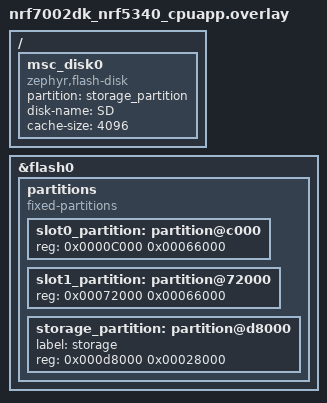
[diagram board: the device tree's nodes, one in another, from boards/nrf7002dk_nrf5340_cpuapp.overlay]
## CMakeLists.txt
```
#
# Copyright (c) 2020 Nordic Semiconductor
#
# SPDX-License-Identifier: LicenseRef-Nordic-5-Clause
#

cmake_minimum_required(VERSION 3.20.0)

find_package(Zephyr REQUIRED HINTS $ENV{ZEPHYR_BASE})
project(download)

# NORDIC SDK APP START
target_sources(app PRIVATE src/main.c)
target_sources(app PRIVATE src/file_storage.c)
# NORDIC SDK APP END
```

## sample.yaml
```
sample:
  name: Download sample
tests:
  sample.net.download.tfm.lte:
    build_only: true
    extra_args: OVERLAY_CONFIG="overlay-tfm.conf"
    integration_platforms:
      - nrf9160dk_nrf9160_ns
    platform_allow: nrf9160dk_nrf9160_ns
    tags: ci_build
  sample.net.download_client.lte:
    build_only: true
    extra_configs:
      - CONFIG_SHELL=y
      - CONFIG_COAP=y
      - CONFIG_DOWNLOAD_CLIENT_SHELL=y
      - CONFIG_SAMPLE_COMPUTE_HASH=y
    integration_platforms:
      - nrf9160dk_nrf9160_ns
    platform_allow: nrf9160dk_nrf9160_ns
    tags: ci_build
  sample.net.download_client.wifi:
    build_only: true
    extra_configs:
      - CONFIG_SHELL=y
      - CONFIG_DOWNLOAD_CLIENT_SHELL=y
      - CONFIG_SAMPLE_COMPUTE_HASH=y
    integration_platforms:
      - nrf7002dk_nrf5340_cpuapp
    platform_allow: nrf7002dk_nrf5340_cpuapp
    tags: ci_build
```

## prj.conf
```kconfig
#
# Copyright (c) 2021 Nordic Semiconductor ASA
#
# SPDX-License-Identifier: LicenseRef-Nordic-5-Clause
#


CONFIG_DOWNLOAD_CLIENT=y
CONFIG_DOWNLOAD_CLIENT_STACK_SIZE=4096

CONFIG_NEWLIB_LIBC=y

# Networking
CONFIG_NETWORKING=y
# CONFIG_NET_SOCKETS_OFFLOAD=y
CONFIG_NET_SOCKETS=y
CONFIG_NET_SOCKETS_POSIX_NAMES=y
CONFIG_NET_IPV4=y
CONFIG_NET_TCP=y
CONFIG_NET_NATIVE=y
CONFIG_MAIN_STACK_SIZE=6144

CONFIG_NET_CONNECTION_MANAGER=y

CONFIG_POSIX_MAX_FDS=16

CONFIG_NET_IPV4_FRAGMENT=y
CONFIG_NET_IPV4_FRAGMENT_MAX_COUNT=5
CONFIG_DOWNLOAD_CLIENT_HTTP_FRAG_SIZE_4096=y
CONFIG_DOWNLOAD_CLIENT_BUF_SIZE=4096
CONFIG_DOWNLOAD_CLIENT_RANGE_REQUESTS=y
CONFIG_DOWNLOAD_CLIENT_LOG_LEVEL_OFF=y

CONFIG_WPA_SUPP_LOG_LEVEL_DBG=y

CONFIG_SAMPLE_SECURE_SOCKET=y
CONFIG_LOG=y
CONFIG_PRINTK=n

CONFIG_NET_TCP_MAX_RECV_WINDOW_SIZE=65535
```

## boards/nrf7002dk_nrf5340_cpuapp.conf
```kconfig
#
# Copyright (c) 2023 Nordic Semiconductor ASA
#
# SPDX-License-Identifier: LicenseRef-Nordic-5-Clause
#

# General
CONFIG_POSIX_CLOCK=y
CONFIG_POSIX_MAX_FDS=10
CONFIG_SYSTEM_WORKQUEUE_STACK_SIZE=4096
CONFIG_HW_STACK_PROTECTION=y

# Optimized networking settings for performance
CONFIG_NRF700X_TX_MAX_DATA_SIZE=512
CONFIG_HEAP_MEM_POOL_SIZE=160000
CONFIG_NET_BUF_DATA_SIZE=1500
CONFIG_NRF700X_QSPI_LOW_POWER=n
CONFIG_NRF_WIFI_LOW_POWER=n
CONFIG_NRF700X_TX_DONE_WQ_ENABLED=n
#CONFIG_NRF700X_TX_DONE_WQ_PRIORITY=-2
CONFIG_NRF700X_RX_WQ_ENABLED=y
CONFIG_NRF700X_RX_WQ_PRIORITY=-3
CONFIG_NRF700X_UTIL=y
CONFIG_NRF700X_MAX_TX_TOKENS=5
CONFIG_NRF700X_RX_NUM_BUFS=63

# Set newlib C to prevent build error complaining that string.h is not supported
CONFIG_NEWLIB_LIBC=y

# Zephyr NET Connection Manager connectivity layer.
CONFIG_L2_WIFI_CONNECTIVITY=y

# Wi-Fi
CONFIG_WIFI=y
CONFIG_WIFI_NRF700X=y
CONFIG_WIFI_LOG_LEVEL_ERR=y
CONFIG_WIFI_MGMT_EXT=y
CONFIG_WIFI_CREDENTIALS=y
CONFIG_WIFI_CREDENTIALS_BACKEND_SETTINGS=y
CONFIG_WIFI_CREDENTIALS_STATIC=y
CONFIG_WIFI_CREDENTIALS_STATIC_SSID=""
CONFIG_WIFI_CREDENTIALS_STATIC_PASSWORD=""
CONFIG_FLASH=y
CONFIG_FLASH_PAGE_LAYOUT=y
CONFIG_FLASH_MAP=y
CONFIG_NVS=y
CONFIG_SETTINGS=y
CONFIG_SETTINGS_NVS=y

# WPA
CONFIG_WPA_SUPP=y
CONFIG_WPA_SUPP_LOG_LEVEL_ERR=y

# NET sockets
CONFIG_NET_L2_ETHERNET=y
CONFIG_NET_TCP_WORKQ_STACK_SIZE=2048
CONFIG_NET_UDP=y
CONFIG_NET_SOCKETS_OFFLOAD=n
CONFIG_NET_DHCPV4=y
CONFIG_NET_CONTEXT_SNDTIMEO=y
CONFIG_NET_CONTEXT_RCVTIMEO=y
CONFIG_NET_MGMT_EVENT_STACK_SIZE=4096

# DNS
CONFIG_DNS_RESOLVER=y

# TLS
CONFIG_NRF_SECURITY=y
CONFIG_MBEDTLS=y
CONFIG_MBEDTLS_ENABLE_HEAP=y
CONFIG_MBEDTLS_HEAP_SIZE=44000
CONFIG_MBEDTLS_RSA_C=y
CONFIG_MBEDTLS_SSL_SERVER_NAME_INDICATION=y
CONFIG_NET_SOCKETS_SOCKOPT_TLS=y

# File storage
CONFIG_DISK_ACCESS=y
CONFIG_FILE_SYSTEM=y
CONFIG_FAT_FILESYSTEM_ELM=y
CONFIG_DISK_DRIVERS=y
CONFIG_DISK_DRIVER_FLASH=y


##################################

CONFIG_DOWNLOAD_CLIENT_BUF_SIZE=16384
CONFIG_DOWNLOAD_CLIENT_RANGE_REQUESTS=n

CONFIG_MBEDTLS_SSL_IN_CONTENT_LEN=16384
CONFIG_MBEDTLS_SSL_OUT_CONTENT_LEN=4096

CONFIG_PSA_WANT_KEY_TYPE_ECC_PUBLIC_KEY=y
CONFIG_CC3XX_BACKEND=y
CONFIG_OBERON_BACKEND=n
CONFIG_PSA_WANT_ECC_SECP_R1_256=y
CONFIG_PSA_WANT_ECC_SECP_R1_384=y

CONFIG_SAMPLE_FILE_CUSTOM=y
CONFIG_SAMPLE_FILE_URL="https://becurienew.s3.ap-south-1.amazonaws.com/test/Sample-WAV_33MB.wav"
CONFIG_SAMPLE_SHA256_HASH="96130acb14c731749c82414063ada50e69493c63944b1f8eff4cfdc891bff40d"

#Disable unused feature to reduce RAM requirement
CONFIG_NET_IPV6=n
CONFIG_MBEDTLS_SSL_SRV_C=n
CONFIG_MBEDTLS_CHACHA20_C=n
CONFIG_MBEDTLS_POLY1305_C=n
CONFIG_MBEDTLS_GCM_C=n
CONFIG_NRF700X_BT_COEX=n
CONFIG_SAMPLE_COMPUTE_HASH=y
CONFIG_SAMPLE_COMPARE_HASH=y
```

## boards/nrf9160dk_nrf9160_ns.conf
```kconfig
#
# Copyright (c) 2023 Nordic Semiconductor ASA
#
# SPDX-License-Identifier: LicenseRef-Nordic-5-Clause
#

# Configuration file for nRF9160 DK
# This file is merged with prj.conf in the application folder, and options
# set here will take precedence if they are present in both files.

# General
CONFIG_HW_STACK_PROTECTION=y
CONFIG_PICOLIBC=y

# Disable Duplicate Address Detection (DAD)
# due to not being properly implemented for offloaded interfaces.
CONFIG_NET_IPV6_NBR_CACHE=n
CONFIG_NET_IPV6_MLD=n

# Connection Manager and Connectivity layer
CONFIG_NET_CONNECTION_MANAGER=y
CONFIG_NET_CONNECTION_MANAGER_STACK_SIZE=1024
CONFIG_LTE_CONNECTIVITY=y
CONFIG_NRF_MODEM_LIB_ON_FAULT_APPLICATION_SPECIFIC=y

# Turn off automatic behavior to give more control to the application
CONFIG_NRF_MODEM_LIB_NET_IF_AUTO_START=n
CONFIG_LTE_CONNECTIVITY_AUTO_CONNECT=n
CONFIG_LTE_CONNECTIVITY_AUTO_DOWN=n

# Certificate handling
CONFIG_MODEM_KEY_MGMT=y
```

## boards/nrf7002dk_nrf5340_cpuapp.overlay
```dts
/*
 * Copyright (c) 2022 Nordic Semiconductor ASA
 *
 * SPDX-License-Identifier: Apache-2.0
 */
/*
 * Copyright (c) 2023 Nordic Semiconductor ASA
 *
 * SPDX-License-Identifier: Apache-2.0
 */

/* Because FAT FS needs at least 64kiB partition and default
 * storage_partition is 32kiB for that board, we need to reorgatnize
 * partitions to get at least 64KiB.
 * This overlay removes image slot partitions and strips each of 64kiB,
 * and removes the storage partition to add the additional 2*64kiB to
 * it.
 */
/delete-node/ &slot0_partition;
/delete-node/ &slot1_partition;
/delete-node/ &storage_partition;

&flash0 {

	partitions {
		compatible = "fixed-partitions";
		#address-cells = <1>;
		#size-cells = <1>;

		slot0_partition: partition@c000 {
			reg = <0x0000C000 0x00066000>;
		};
		slot1_partition: partition@72000 {
			reg = <0x00072000 0x00066000>;
		};

		storage_partition: partition@d8000 {
			label = "storage";
			reg = <0x000d8000 0x00028000>;
		};
	};
};

/ {
	msc_disk0 {
		status="okay";
		compatible = "zephyr,flash-disk";
		partition = <&storage_partition>;
		disk-name = "SD";
		/* cache-size == page erase size */
		cache-size = <4096>;
	};
};
```

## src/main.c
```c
/*
 * Copyright (c) 2020 Nordic Semiconductor ASA
 *
 * SPDX-License-Identifier: LicenseRef-Nordic-5-Clause
 */

#include <string.h>
#include <stdlib.h>
#include <zephyr/kernel.h>
#if defined(CLOCK_FEATURE_HFCLK_DIVIDE_PRESENT) || NRF_CLOCK_HAS_HFCLK192M
#include <nrfx_clock.h>
#endif
#include <zephyr/net/socket.h>
#include <zephyr/net/net_if.h>
#include <zephyr/net/conn_mgr_connectivity.h>
#include <net/download_client.h>

#if CONFIG_MODEM_KEY_MGMT
#include <modem/modem_key_mgmt.h>
#else
#include <zephyr/net/tls_credentials.h>
#endif
/*
extern int file_storage_init(void);
extern int file_storage_read(uint8_t *const buf, const size_t buf_size);
extern int file_storage_write(const uint8_t *const buf, const size_t buf_size);
extern int file_storage_write_stream_start(void);
extern int file_storage_write_stream_stop(void);
extern int file_storage_write_stream_fragment(const uint8_t *const buf, const size_t buf_size);
extern void file_storage_lsdir(void);
*/
#define URL CONFIG_SAMPLE_FILE_URL
#define SEC_TAG CONFIG_SAMPLE_SEC_TAG

/* Macros used to subscribe to specific Zephyr NET management events. */
#define L4_EVENT_MASK (NET_EVENT_L4_CONNECTED | NET_EVENT_L4_DISCONNECTED)
#define CONN_LAYER_EVENT_MASK (NET_EVENT_CONN_IF_FATAL_ERROR)

#define PROGRESS_WIDTH 50
#define STARTING_OFFSET 0

/* Zephyr NET management event callback structures. */
static struct net_mgmt_event_callback l4_cb;
static struct net_mgmt_event_callback conn_cb;
static struct net_if *net_if;

static K_SEM_DEFINE(network_connected_sem, 0, 1);
static K_SEM_DEFINE(file_downloaded_sem, 0, 1);

#if CONFIG_SAMPLE_SECURE_SOCKET
static const char cert[] = {
	#include CONFIG_SAMPLE_CERT_FILE
};
static int sec_tag_list[] = { SEC_TAG };
BUILD_ASSERT(sizeof(cert) < KB(4), "Certificate too large");
#endif

static struct download_client downloader;
static struct download_client_cfg config = {
#if CONFIG_SAMPLE_SECURE_SOCKET
	.sec_tag_list = sec_tag_list,
	.sec_tag_count = ARRAY_SIZE(sec_tag_list),
	.set_tls_hostname = true,
#endif
};

#if CONFIG_SAMPLE_COMPUTE_HASH
#include <mbedtls/sha256.h>
static mbedtls_sha256_context sha256_ctx;
#endif

static int64_t ref_time;

#if CONFIG_SAMPLE_SECURE_SOCKET
static int cert_provision(void)
{
	int err;

	printk("Provisioning certificate\n");

#if CONFIG_MODEM_KEY_MGMT
	bool exists;

	err = modem_key_mgmt_exists(SEC_TAG,
				    MODEM_KEY_MGMT_CRED_TYPE_CA_CHAIN,
				    &exists);
	if (err) {
		printk("Failed to check for certificates err %d\n", err);
		return err;
	}

	if (exists) {
		printk("Certificate ");
		/* Let's compare the existing credential */
		err = modem_key_mgmt_cmp(SEC_TAG,
					 MODEM_KEY_MGMT_CRED_TYPE_CA_CHAIN,
					 cert, sizeof(cert) - 1);

		printk("%s\n", err ? "mismatch" : "match");

		if (!err) {
			return 0;
		}
	}

	/*  Provision certificate to the modem */
	err = modem_key_mgmt_write(SEC_TAG,
				   MODEM_KEY_MGMT_CRED_TYPE_CA_CHAIN,
				   cert, sizeof(cert) - 1);
	if (err) {
		printk("Failed to provision certificate, err %d\n", err);
		return err;
	}
#else /* CONFIG_MODEM_KEY_MGMT */
	err = tls_credential_add(SEC_TAG,
				 TLS_CREDENTIAL_CA_CERTIFICATE,
				 cert,
				 sizeof(cert));
	if (err < 0) {
		printk("Failed to register CA certificate: %d\n", err);
		return err;
	}
#endif /* !CONFIG_MODEM_KEY_MGMT */

	return 0;
}
#endif

static void on_net_event_l4_disconnected(void)
{
	printk("Disconnected from network\n");
}

static void on_net_event_l4_connected(void)
{
	k_sem_give(&network_connected_sem);
}

static void l4_event_handler(struct net_mgmt_event_callback *cb,
			     uint32_t event,
			     struct net_if *iface)
{
	switch (event) {
	case NET_EVENT_L4_CONNECTED:
		printk("IP Up\n");
		on_net_event_l4_connected();
		break;
	case NET_EVENT_L4_DISCONNECTED:
		printk("IP down\n");
		on_net_event_l4_disconnected();
		break;
	default:
		break;
	}
}

static void connectivity_event_handler(struct net_mgmt_event_callback *cb,
				       uint32_t event,
				       struct net_if *iface)
{
	if (event == NET_EVENT_CONN_IF_FATAL_ERROR) {
		printk("Fatal error received from the connectivity layer, rebooting\n");
		return;
	}
}

static void progress_print(size_t downloaded, size_t file_size)
{
	const int percent = (downloaded * 100) / file_size;
	size_t lpad = (percent * PROGRESS_WIDTH) / 100;
	size_t rpad = PROGRESS_WIDTH - lpad;

	printk("\r[ %3d%% ] |", percent);
	for (size_t i = 0; i < lpad; i++) {
		printk("=");
	}
	for (size_t i = 0; i < rpad; i++) {
		printk(" ");
	}
	printk("| (%d/%d bytes)", downloaded, file_size);
}

static int callback(const struct download_client_evt *event)
{
	static size_t downloaded;
	static size_t file_size;
	uint32_t speed;
	int64_t ms_elapsed;

	if (downloaded == 0) {
		download_client_file_size_get(&downloader, &file_size);
		downloaded += STARTING_OFFSET;
	}

	switch (event->id) {
	case DOWNLOAD_CLIENT_EVT_FRAGMENT:
		downloaded += event->fragment.len;
		if (file_size) {
			//progress_print(downloaded, file_size);
		} else {
			//printk("\r[ %d bytes ] \n", downloaded);
		}

		// int rc = file_storage_write_stream_fragment(event->fragment.buf, event->fragment.len);
		// if (rc < 0) {
		// 	printk("Failed to store fragment, error: %d\n", rc);
		// } else {
		// 	//printk("Stored fragment of size %d to file\n", rc);
		// }
#if CONFIG_SAMPLE_COMPUTE_HASH
		mbedtls_sha256_update(&sha256_ctx, event->fragment.buf, event->fragment.len);
#endif
		return 0;

	case DOWNLOAD_CLIENT_EVT_DONE:
		ms_elapsed = k_uptime_delta(&ref_time);
		speed = ((float)file_size / ms_elapsed) * MSEC_PER_SEC;

		// (void)file_storage_write_stream_stop();

		printk("\nDownload completed in %lld ms @ %d bytes per sec, total %d bytes\n",
		       ms_elapsed, speed, downloaded);

#if CONFIG_SAMPLE_COMPUTE_HASH
		uint8_t hash[32];
		uint8_t hash_str[64 + 1];

		mbedtls_sha256_finish(&sha256_ctx, hash);
		mbedtls_sha256_free(&sha256_ctx);

		bin2hex(hash, sizeof(hash), hash_str, sizeof(hash_str));

		printk("SHA256: %s\n", hash_str);

#if CONFIG_SAMPLE_COMPARE_HASH
		if (strcmp(hash_str, CONFIG_SAMPLE_SHA256_HASH)) {
			printk("Expect: %s\n", CONFIG_SAMPLE_SHA256_HASH);
			printk("SHA256 mismatch!\n");
		}
#endif /* CONFIG_SAMPLE_COMPARE_HASH */
#endif /* CONFIG_SAMPLE_COMPUTE_HASH */

		//(void)conn_mgr_if_disconnect(net_if);
		// file_storage_lsdir();
		printk("Bye\n");
		return 0;

	case DOWNLOAD_CLIENT_EVT_ERROR:
		// (void)file_storage_write_stream_stop();

		printk("Error %d during download\n", event->error);
		if (event->error == -ECONNRESET) {
			/* With ECONNRESET, allow library to attempt a reconnect by returning 0 */
		} else {
			//(void)conn_mgr_if_disconnect(net_if);
			/* Stop download */
			return -1;
		}
		break;
	case DOWNLOAD_CLIENT_EVT_CLOSED:
		// (void)file_storage_write_stream_stop();
		printk("Socket closed\n");
		k_sem_give(&file_downloaded_sem);
		break;
	}

	return 0;
}

int main(void)
{
	int err;

#if defined(CLOCK_FEATURE_HFCLK_DIVIDE_PRESENT) || NRF_CLOCK_HAS_HFCLK192M
	/* For now hardcode to 128MHz */
	int ret;
	/*
	nrfx_clock_divider_set(NRF_CLOCK_DOMAIN_HFCLK,
			       NRF_CLOCK_HFCLK_DIV_1);
			       */
	ret = nrfx_clock_divider_set(NRF_CLOCK_DOMAIN_HFCLK, NRF_CLOCK_HFCLK_DIV_1);
	ret -= NRFX_ERROR_BASE_NUM;
	if (ret) {
		return ret;
	}

	nrfx_clock_hfclk_start();
	while (!nrfx_clock_hfclk_is_running()) {
	}

#endif
	printk("Starting %s with CPU frequency: %d MHz\n", CONFIG_BOARD, SystemCoreClock/MHZ(1));
/*
	if (file_storage_init()) {
		printk("EXIT\n");
		return 0;
	}
*/
	printk("Download client sample started\n");

	net_if = net_if_get_default();
	if (net_if == NULL) {
		printk("Pointer to network interface is NULL\n");
		return -ECANCELED;
	}

	/* Setup handler for Zephyr NET Connection Manager events. */
	net_mgmt_init_event_callback(&l4_cb, l4_event_handler, L4_EVENT_MASK);
	net_mgmt_add_event_callback(&l4_cb);

	/* Setup handler for Zephyr NET Connection Manager Connectivity layer. */
	net_mgmt_init_event_callback(&conn_cb, connectivity_event_handler, CONN_LAYER_EVENT_MASK);
	net_mgmt_add_event_callback(&conn_cb);

#if CONFIG_SAMPLE_SECURE_SOCKET
	/* Provision certificates before connecting to the network */
	err = cert_provision();
	if (err) {
		return 0;
	}
#endif

	/* Add temporary fix to prevent using Wi-Fi before WPA supplicant is ready. */
	/* Remove this whenever wpa supplicant ready events has been added. */
	k_sleep(K_SECONDS(1));

	printk("Connecting to network\n");

	err = conn_mgr_if_connect(net_if);
	if (err) {
		printk("conn_mgr_if_connect, error: %d\n", err);
		return err;
	}

	k_sem_take(&network_connected_sem, K_FOREVER);

	printk("Network connected\n");
	k_sleep(K_SECONDS(5));
	while(1) {
		printk("Start connecting\n");
		err = download_client_init(&downloader, callback);
		if (err) {
			printk("Failed to initialize the client, err %d", err);
			return 0;
		}

	#if CONFIG_SAMPLE_COMPUTE_HASH
		mbedtls_sha256_init(&sha256_ctx);
		mbedtls_sha256_starts(&sha256_ctx, false);
	#endif

		// err = file_storage_write_stream_start();
		// if (err) {
		// 	printk("Failed to start write stream: %d\n", err);
		// 	return 0;
		// }
		ref_time = k_uptime_get();


		err = download_client_get(&downloader, URL, &config, URL, STARTING_OFFSET);
		if (err) {
			printk("Failed to start the downloader, err %d", err);
		/*
			err = file_storage_write_stream_stop();
			if (err) {
				printk("Failed to stop write stream: %d\n", err);
			}
		*/
			return 0;
		}

		printk("Downloading %s\n", URL);
		k_sem_take(&file_downloaded_sem, K_FOREVER);
		/*
		err = download_client_disconnect(&downloader);
		if (err) {
			printk("Failed to disconnect the downloader, err %d", err);
		}
		*/
		k_sleep(K_SECONDS(5));
	}
	return 0;
}
```

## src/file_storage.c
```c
#include <zephyr/kernel.h>
#include <zephyr/device.h>
#include <zephyr/storage/disk_access.h>
#include <zephyr/logging/log.h>
#include <zephyr/fs/fs.h>
#include <ff.h>

LOG_MODULE_REGISTER(fs_test);

#define DISK_DRIVE_NAME			"SD"
#define DISK_MOUNT_PT			"/" DISK_DRIVE_NAME ":"
#define MAX_PATH 			128
#define DOWNLOADED_FILE_NAME		"file.bin"
#define DOWNLOADED_FILE_PATH		DISK_MOUNT_PT "/" DOWNLOADED_FILE_NAME
#define SOME_REQUIRED_LEN		MAX(sizeof(DOWNLOADED_FILE_NAME), sizeof(SOME_DIR_NAME))

static FATFS fat_fs;
/* mounting info */
static struct fs_mount_t mp = {
	.type = FS_FATFS,
	.fs_data = &fat_fs,
};

static const char *disk_mount_pt = DISK_MOUNT_PT;

static int lsdir(const char *path)
{
	int res;
	struct fs_dir_t dirp;
	static struct fs_dirent entry;
	int count = 0;

	fs_dir_t_init(&dirp);

	/* Verify fs_opendir() */
	res = fs_opendir(&dirp, path);
	if (res) {
		printk("Error opening dir %s [%d]\n", path, res);
		return res;
	}

	printk("\nListing dir %s ...\n", path);
	for (;;) {
		/* Verify fs_readdir() */
		res = fs_readdir(&dirp, &entry);

		/* entry.name[0] == 0 means end-of-dir */
		if (res || entry.name[0] == 0) {
			break;
		}

		if (entry.type == FS_DIR_ENTRY_DIR) {
			printk("[DIR ] %s\n", entry.name);
		} else {
			printk("[FILE] %s (size = %zu)\n",
				entry.name, entry.size);
		}
		count++;
	}

	/* Verify fs_closedir() */
	fs_closedir(&dirp);
	if (res == 0) {
		res = count;
	}

	return res;
}



int file_storage_init(void)
{

        static const char *disk_pdrv = DISK_DRIVE_NAME;
        uint32_t memory_size_kb;
        uint32_t sector_count;
        uint32_t sector_size;

        if (disk_access_init(disk_pdrv) != 0) {
                LOG_ERR("Storage init ERROR!");
                return -1;
        }

        if (disk_access_ioctl(disk_pdrv, DISK_IOCTL_GET_SECTOR_COUNT, &sector_count)) {
                LOG_ERR("Unable to get sector count");
                return -1;
        }
        LOG_INF("Block count %u", sector_count);

        if (disk_access_ioctl(disk_pdrv, DISK_IOCTL_GET_SECTOR_SIZE, &sector_size)) {
                LOG_ERR("Unable to get sector size");
                return -1;
        }
        LOG_INF("Sector size %u", sector_size);

        memory_size_kb = (uint32_t)(sector_count * sector_size) >> 10;
        LOG_INF("Memory Size (kB): %u", memory_size_kb);

	mp.mnt_point = disk_mount_pt;

	int res = fs_mount(&mp);

	if (res == FR_OK) {
		LOG_INF("Disk mounted");
	} else {
		LOG_ERR("Error mounting disk: %d", res);

		return -1;
	}

	return 0;
}



int file_storage_read(uint8_t *const buf, const size_t buf_size)
{
	struct fs_file_t file;
	int rc;
	char *fname = DOWNLOADED_FILE_PATH;

	fs_file_t_init(&file);

	rc = fs_open(&file, fname, FS_O_CREATE | FS_O_READ);
	if (rc < 0) {
		LOG_ERR("Failed to open file '%s': %d", fname, rc);
		return rc;
	}

	rc = fs_read(&file, buf, buf_size);
	if (rc < 0) {
		LOG_ERR("Failed to read from file '%s': %d", fname, rc);
	}

	if (fs_close(&file)) {
		LOG_ERR("Failed to close file '%s'", fname);
	}

	return rc;
}

int file_storage_write(const uint8_t *const buf, const size_t buf_size)
{
	struct fs_file_t file;
	int rc;
	char *fname = DOWNLOADED_FILE_PATH;

	fs_file_t_init(&file);

	rc = fs_open(&file, fname, FS_O_CREATE | FS_O_WRITE);
	if (rc < 0) {
		LOG_ERR("Failed to open file '%s': %d", fname, rc);
		return rc;
	}

	rc = fs_seek(&file, 0, FS_SEEK_SET);
	if (rc < 0) {
		LOG_ERR("Failed to set file position in '%s': %d", fname, rc);
		goto out;
	}

	rc = fs_write(&file, buf, buf_size);
	if (rc < 0) {
		LOG_ERR("Failed to write data to '%s': %d", fname, rc);
	}

out:
	if (fs_close(&file)) {
		LOG_ERR("Failed to close file '%s'", fname);
	}

	return rc;
}

static struct fs_file_t stream_file;

int file_storage_write_stream_start(void)
{
	int rc;
	char *fname = DOWNLOADED_FILE_PATH;

	fs_file_t_init(&stream_file);

	rc = fs_open(&stream_file, fname, FS_O_CREATE | FS_O_WRITE);
	if (rc < 0) {
		LOG_ERR("Failed to open file '%s': %d", fname, rc);
		return rc;
	}

	rc = fs_seek(&stream_file, 0, FS_SEEK_SET);
	if (rc < 0) {
		LOG_ERR("Failed to set file position in '%s': %d", fname, rc);

		if (fs_close(&stream_file)) {
			LOG_ERR("Failed to close file '%s'", fname);
		}

		return rc;
	}

	return 0;
}

int file_storage_write_stream_stop(void)
{
	int rc;

	rc = fs_close(&stream_file);
	if (rc) {
		LOG_ERR("Failed to close stream file");
	}

	return rc;
}

int file_storage_write_stream_fragment(const uint8_t *const buf, const size_t buf_size)
{
	int rc;

	rc = fs_write(&stream_file, buf, buf_size);
	if (rc < 0) {
		LOG_ERR("Failed to write data to stream file: %d", rc);
	}

	return rc;
}

void file_storage_lsdir(void)
{
	lsdir(disk_mount_pt);
}
```
